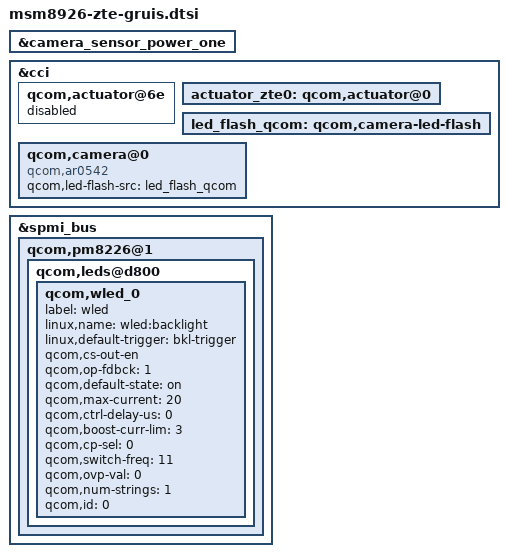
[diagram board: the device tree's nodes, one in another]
/include/ "touch-key-backlight_gruis.dtsi"
/include/ "msm8226-camera-sensor-zte.dtsi"

&camera_sensor_power_one {
	status = "ok";
};

&cci {

	/*disable qcom actuator because it is not used*/
	qcom,actuator@6e {
		status = "disabled";
	};
	
	/*enable the true actuator*/
	actuator_zte0: qcom,actuator@0 {
		status = "ok";
	};
	led_flash_qcom: qcom,camera-led-flash {
		status = "ok";
	};
	qcom,camera@0 {
		compatible = "qcom,ar0542";
		qcom,led-flash-src = <&led_flash_qcom>;
	};

};

&spmi_bus {
	qcom,pm8226@1 {
		qcom,leds@d800 {
			status = "okay";
			qcom,wled_0 {
				label = "wled";
				linux,name = "wled:backlight";
				linux,default-trigger = "bkl-trigger";
				qcom,cs-out-en;
				qcom,op-fdbck = <1>;
				qcom,default-state = "on";
				qcom,max-current = <20>;
				qcom,ctrl-delay-us = <0>;
				qcom,boost-curr-lim = <3>;
				qcom,cp-sel = <0>;
				qcom,switch-freq = <11>;
				qcom,ovp-val = <0>;
				qcom,num-strings = <1>;
				qcom,id = <0>;
			};
		};

	};
};

